# f2837xd_clk_cfg_regs register map
Vendor: Texas Instruments
Peripheral module from a debugger description file (folder C2000).
Address unit: 16 bits
Registers are 32-bit, read-write, no defined reset value unless marked. A register's access mark holds for its fields unless they carry their own. Offsets are as the file gives them; lines under a group give offsets from that group; [hi:lo] are bit positions; {n}, {i} and the like mark numbered series; 'fields as' and 'values as' point back to an identical list; <NAME> marks a mode.

## CLK_CFG_REGS — CLK CFG Registers
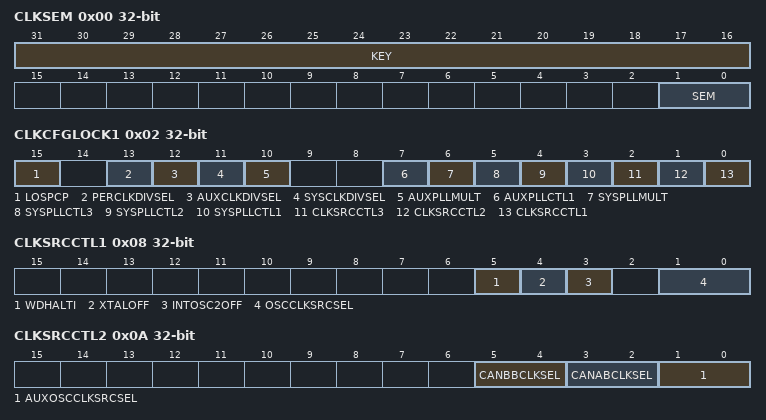
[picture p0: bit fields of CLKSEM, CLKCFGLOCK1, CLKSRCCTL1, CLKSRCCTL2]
0x00 CLKSEM access not given — Clock Control Semaphore Register
  [31:16] KEY — Key Qualifier for writes to this register (access R=0/W)
  [1:0] SEM rw — Semaphore for CLKCFG Ownership by CPU1 or CPU2
0x02 CLKCFGLOCK1 access not given — Lock bit for CLKCFG registers
  [15] LOSPCP — Lock bit for LOSPCP register (access R/SOnce)
  [13] PERCLKDIVSEL — Lock bit for PERCLKDIVSEL register (access R/SOnce)
  [12] AUXCLKDIVSEL — Lock bit for AUXCLKDIVSEL register (access R/SOnce)
  [11] SYSCLKDIVSEL — Lock bit for SYSCLKDIVSEL register (access R/SOnce)
  [10] AUXPLLMULT — Lock bit for AUXPLLMULT register (access R/SOnce)
  [7] AUXPLLCTL1 — Lock bit for AUXPLLCTL1 register (access R/SOnce)
  [6] SYSPLLMULT — Lock bit for SYSPLLMULT register (access R/SOnce)
  [5] SYSPLLCTL3 — Lock bit for SYSPLLCTL3 register (access R/SOnce)
  [4] SYSPLLCTL2 — Lock bit for SYSPLLCTL2 register (access R/SOnce)
  [3] SYSPLLCTL1 — Lock bit for SYSPLLCTL1 register (access R/SOnce)
  [2] CLKSRCCTL3 — Lock bit for CLKSRCCTL3 register (access R/SOnce)
  [1] CLKSRCCTL2 — Lock bit for CLKSRCCTL2 register (access R/SOnce)
  [0] CLKSRCCTL1 — Lock bit for CLKSRCCTL1 register (access R/SOnce)
0x08 CLKSRCCTL1 — Clock Source Control register-1
  [5] WDHALTI — Watchdog HALT Mode Ignore Bit
  [4] XTALOFF — Crystal (External) Oscillator Off Bit
  [3] INTOSC2OFF — Internal Oscillator 2 Off Bit
  [1:0] OSCCLKSRCSEL — OSCCLK Source Select Bit
0x0A CLKSRCCTL2 — Clock Source Control register-2
  [5:4] CANBBCLKSEL — CANB Bit Clock Source Select Bit
  [3:2] CANABCLKSEL — CANA Bit Clock Source Select Bit
  [1:0] AUXOSCCLKSRCSEL — AUXOSCCLK Source Select Bit
0x0C CLKSRCCTL3 — Clock Source Control register-3
  [2:0] XCLKOUTSEL — XCLKOUT Source Select Bit
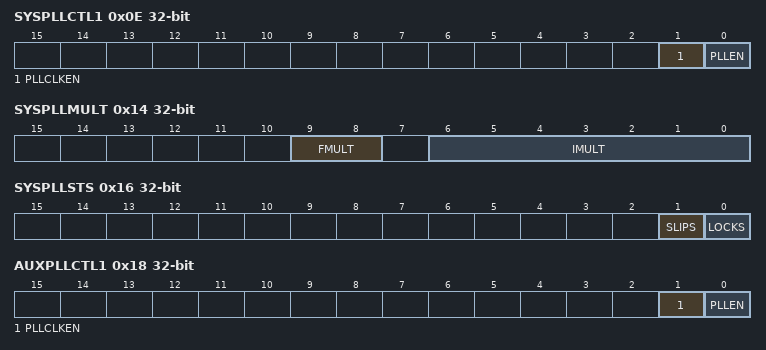
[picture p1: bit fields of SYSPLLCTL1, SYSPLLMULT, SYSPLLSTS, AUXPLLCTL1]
0x0E SYSPLLCTL1 — SYSPLL Control register-1
  [1] PLLCLKEN — SYSPLL bypassed or included in the PLLSYSCLK path
  [0] PLLEN — SYSPLL enable/disable bit
0x14 SYSPLLMULT — SYSPLL Multiplier register
  [9:8] FMULT — SYSPLL Fractional Multiplier
  [6:0] IMULT — SYSPLL Integer Multiplier
0x16 SYSPLLSTS ro — SYSPLL Status register
  [1] SLIPS — SYSPLL Slip Status Bit
  [0] LOCKS — SYSPLL Lock Status Bit
0x18 AUXPLLCTL1 — AUXPLL Control register-1
  [1] PLLCLKEN — AUXPLL bypassed or included in the AUXPLLCLK path
  [0] PLLEN — AUXPLL enable/disable bit
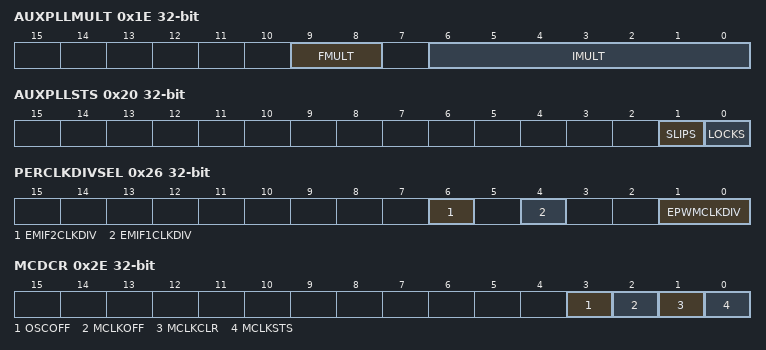
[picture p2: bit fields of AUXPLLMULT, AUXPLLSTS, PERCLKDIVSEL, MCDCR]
0x1E AUXPLLMULT — AUXPLL Multiplier register
  [9:8] FMULT — AUXPLL Fractional Multiplier
  [6:0] IMULT — AUXPLL Integer Multiplier
0x20 AUXPLLSTS ro — AUXPLL Status register
  [1] SLIPS — AUXPLL Slip Status Bit
  [0] LOCKS — AUXPLL Lock Status Bit
0x22 SYSCLKDIVSEL — System Clock Divider Select register
  [5:0] PLLSYSCLKDIV — PLLSYSCLK Divide Select
0x24 AUXCLKDIVSEL — Auxillary Clock Divider Select register
  [1:0] AUXPLLDIV — AUXPLLCLK Divide Select
0x26 PERCLKDIVSEL — Peripheral Clock Divider Selet register
  [6] EMIF2CLKDIV — EMIF2 Clock Divide Select
  [4] EMIF1CLKDIV — EMIF1 Clock Divide Select
  [1:0] EPWMCLKDIV — EPWM Clock Divide Select
0x28 XCLKOUTDIVSEL — XCLKOUT Divider Select register
  [1:0] XCLKOUTDIV — XCLKOUT Divide Select
0x2C LOSPCP — Low Speed Clock Source Prescalar
  [2:0] LSPCLKDIV — LSPCLK Divide Select
0x2E MCDCR access not given — Missing Clock Detect Control Register
  [3] OSCOFF rw — Oscillator Clock Off Bit
  [2] MCLKOFF rw — Missing Clock Detect Off Bit
  [1] MCLKCLR — Missing Clock Clear Bit (access R=0/W=1)
  [0] MCLKSTS ro — Missing Clock Status Bit
0x30 X1CNT ro — 10-bit Counter on X1 Clock
  [9:0] X1CNT — X1 Counter
